# Z20K14xM register map
Vendor: Zhixin Semiconductor; Series: Z20K14xM; File version: 0.1.0
CPU: CM4 r0p1, little endian, no MPU, FPU, 4 interrupt priority bits
Registers are 32-bit, read-write, reset 0x0 unless marked. A register's access mark holds for its fields unless they carry their own. Offsets are from the block's base; [hi:lo] are bit positions.

## PMU
Base 0x4007D000
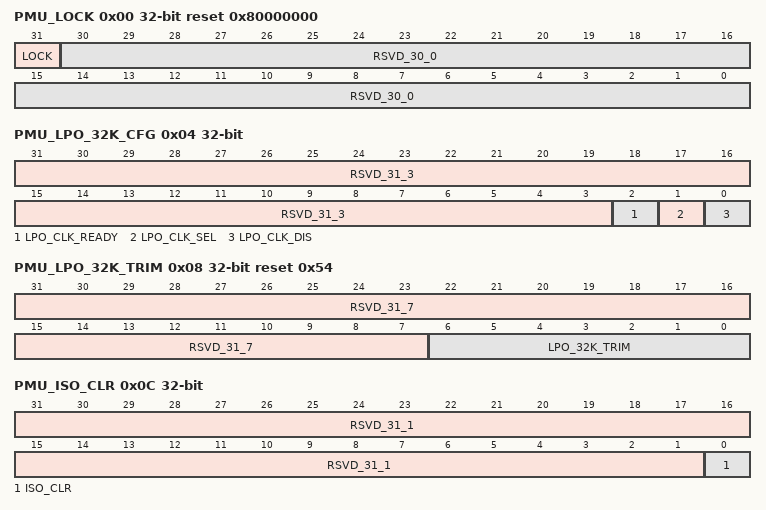
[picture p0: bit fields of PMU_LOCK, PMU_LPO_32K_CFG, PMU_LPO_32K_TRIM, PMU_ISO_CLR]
0x00 PMU_LOCK reset 0x80000000 — PMU lock protection register(PMU_LOCK_USER)
  [31] LOCK — PMU LOCK protection bit.
  [30:0] RSVD_30_0 — reserve
0x04 PMU_LPO_32K_CFG — PMU LPO32K control register(PMU_LPO32K_CFG)
  [31:3] RSVD_31_3 — reserve
  [2] LPO_CLK_READY — LPO raw clock ready flag.
  [1] LPO_CLK_SEL — LPO clock select bit.
  [0] LPO_CLK_DIS — LPO clock disable bit
0x08 PMU_LPO_32K_TRIM reset 0x54 — PMU LPO32K trim reigster(PMU_LPO32K_TRIM)
  [31:7] RSVD_31_7 — reserve
  [6:0] LPO_32K_TRIM
0x0C PMU_ISO_CLR — PMU isolation clear register(PMU_ISO_CLR)
  [31:1] RSVD_31_1 — reserve
  [0] ISO_CLR — isolation w1c clear bit.
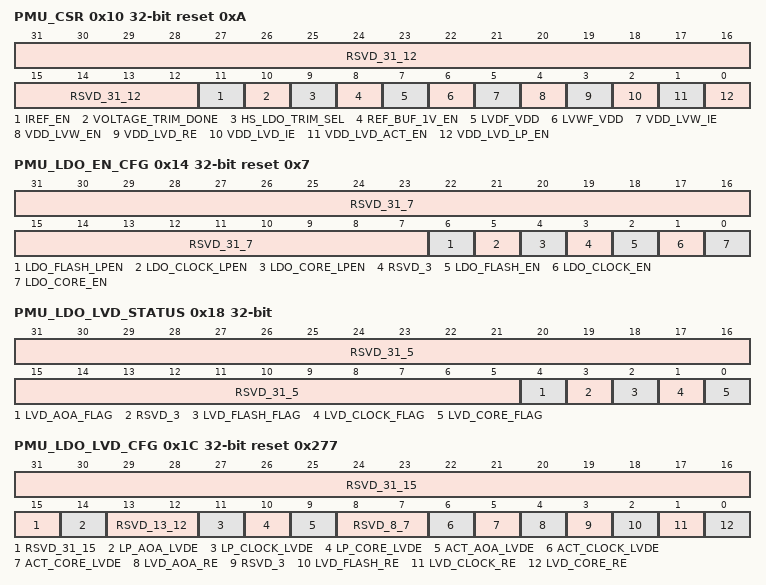
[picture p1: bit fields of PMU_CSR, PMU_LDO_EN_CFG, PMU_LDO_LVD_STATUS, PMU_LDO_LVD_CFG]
0x10 PMU_CSR reset 0xA — PMU control and status register(PMU_CSR)
  [31:12] RSVD_31_12 — reserve
  [11] IREF_EN — iref1uA enable bit
  [10] VOLTAGE_TRIM_DONE — voltage trim done flag
  [9] HS_LDO_TRIM_SEL — high speed trim select bit
  [8] REF_BUF_1V_EN — Reference 1V output enable with buf control
  [7] LVDF_VDD — VDD5v LVD flag
  [6] LVWF_VDD — VDD5v LVW detect flag
  [5] VDD_LVW_IE — VDD5v LVW interrupt enable
  [4] VDD_LVW_EN — VDD5v LVW detect control bit.
  [3] VDD_LVD_RE — VDD5v LVD reset enable control bit
  [2] VDD_LVD_IE — VDD5v LVD interrupt enable control
  [1] VDD_LVD_ACT_EN — VDD5v LVD detect control bit under active mode
  [0] VDD_LVD_LP_EN — VDD5v LVD detect control bit under low power mode
0x14 PMU_LDO_EN_CFG reset 0x7 — PMU LDO enable configure register(PMU_LDO_EN_CFG)
  [31:7] RSVD_31_7 — reserve
  [6] LDO_FLASH_LPEN — LDO-flash low drive strength mode enable under stop mode
  [5] LDO_CLOCK_LPEN — LDO-clock low drive strength mode enable under stop mode
  [4] LDO_CORE_LPEN — LDO-core low drive strength enable uner stop mode
  [3] RSVD_3 — reserve
  [2] LDO_FLASH_EN — LDO-flash regulator enable control
  [1] LDO_CLOCK_EN — LDO-clock regulator enable control
  [0] LDO_CORE_EN — LDO-core regulator enable control
0x18 PMU_LDO_LVD_STATUS — PMU LDO LVD status register(PMU_LDO_LVD_STATUS)
  [31:5] RSVD_31_5 — reserve
  [4] LVD_AOA_FLAG — always-on analog LDO LVD flag
  [3] RSVD_3 — reserve
  [2] LVD_FLASH_FLAG — LDO flash LVD flag
  [1] LVD_CLOCK_FLAG — LDO clock LVD flag
  [0] LVD_CORE_FLAG — LDO core LVD flag
0x1C PMU_LDO_LVD_CFG reset 0x277 — PMU LDO LVD configure register(PMU_LDO_LVD_CFG)
  [31:15] RSVD_31_15 — reserve
  [14] LP_AOA_LVDE — PMU always-on LDO-aoa LVD detect control under low power mode
  [13:12] RSVD_13_12 — reserve
  [11] LP_CLOCK_LVDE — PMU LDO-clock LVD detect control under low power mode
  [10] LP_CORE_LVDE — PMU LDO-core LVD detect control under low power mode
  [9] ACT_AOA_LVDE — PMU LDO-aoa LVD detect control under active mode
  [8:7] RSVD_8_7 — reserve
  [6] ACT_CLOCK_LVDE — PMU LDO-clock LVD detect control under active mode
  [5] ACT_CORE_LVDE — PMU LDO-core LVD detect control under active mode
  [4] LVD_AOA_RE — PMU LDO-aoa LVD reset enable control
  [3] RSVD_3 — reserve
  [2] LVD_FLASH_RE — PMU LDO-flash LVD reset enable control
  [1] LVD_CLOCK_RE — PMU LDO-clock LVD reset enable control
  [0] LVD_CORE_RE — PMU LDO-core LVD reset enable control
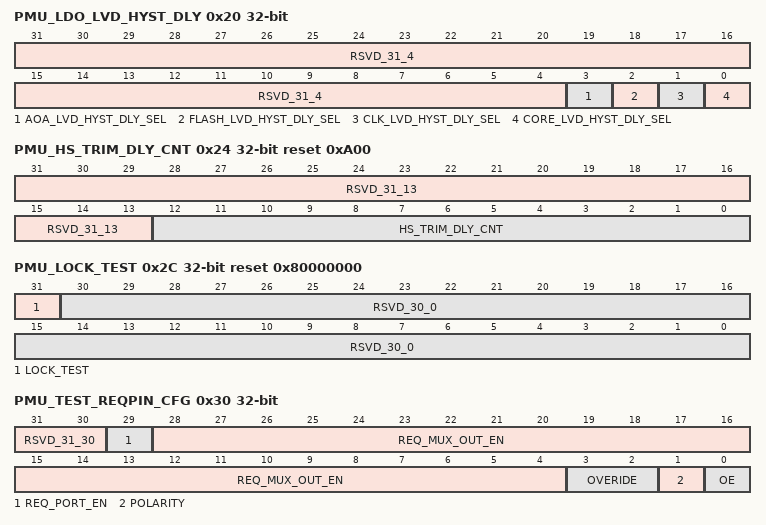
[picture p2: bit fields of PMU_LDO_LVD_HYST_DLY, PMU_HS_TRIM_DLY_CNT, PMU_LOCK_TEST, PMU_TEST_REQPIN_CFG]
0x20 PMU_LDO_LVD_HYST_DLY — PMU LDO LVD delay configure register(PMU_LVD_HYST_DLY)
  [31:4] RSVD_31_4 — reserve
  [3] AOA_LVD_HYST_DLY_SEL — aoa-lvd_hyst select
  [2] FLASH_LVD_HYST_DLY_SEL — flash-lvd_hyst select
  [1] CLK_LVD_HYST_DLY_SEL — clk-lvd_hyst select
  [0] CORE_LVD_HYST_DLY_SEL — core-lvd_hyst select
0x24 PMU_HS_TRIM_DLY_CNT reset 0xA00 — PMU reserve1 register (PMU_RESERVE1)
  [31:13] RSVD_31_13 — reserve
  [12:0] HS_TRIM_DLY_CNT — delay counter for switch between hsrun and run
0x28 PMU_RESERVE2 — PMU reserve2 register (PMU_RESERVE2)
  [31:0] RSVD_31_0 — reserve
0x2C PMU_LOCK_TEST reset 0x80000000 — reserve for user , doest not suggest user write this regsiter though no hardfault during write access. PMU lock protection for PMU test mode registers(PMU_LOCK_TEST)
  [31] LOCK_TEST — PMU LOCK test protection bit
  [30:0] RSVD_30_0 — reserve
0x30 PMU_TEST_REQPIN_CFG — PMU request pin observe register(PMU_TEST_REQPIN)
  [31:30] RSVD_31_30 — reserve
  [29] REQ_PORT_EN — Request pin port enable control
  [28:4] REQ_MUX_OUT_EN — Request pin mux output
  [3:2] OVERIDE — Request pin override enable
  [1] POLARITY — Request pin polarity control
  [0] OE — Request pin output enable
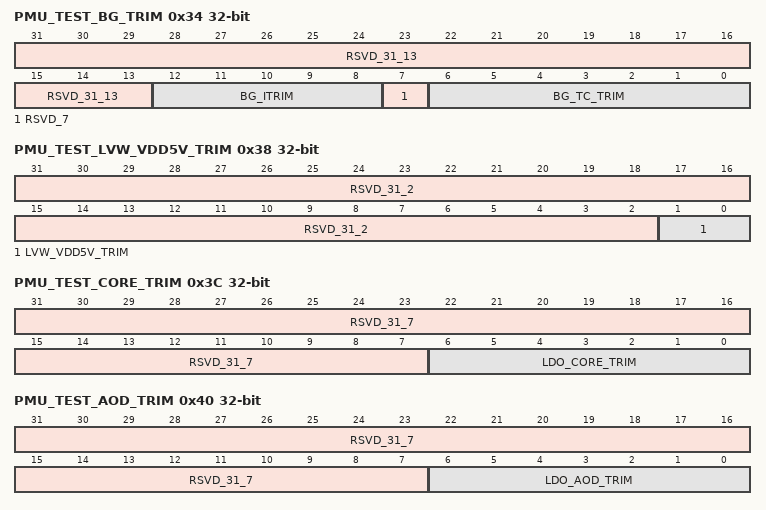
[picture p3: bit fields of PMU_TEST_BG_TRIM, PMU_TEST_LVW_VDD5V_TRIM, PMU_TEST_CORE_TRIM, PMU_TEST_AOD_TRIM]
0x34 PMU_TEST_BG_TRIM — PMU test bangap trim register(PMU_TEST_BG_TRIM)
  [31:13] RSVD_31_13 — reserve
  [12:8] BG_ITRIM — BandGap current reference trim
  [7] RSVD_7 — reserve
  [6:0] BG_TC_TRIM — Bandgap temperature trim
0x38 PMU_TEST_LVW_VDD5V_TRIM — PMU test LVW VDD5V trim register(PMU_TEST_LVW_VDD5V_TRIM)
  [31:2] RSVD_31_2 — reserve
  [1:0] LVW_VDD5V_TRIM — VDD5v LVW trim bits
0x3C PMU_TEST_CORE_TRIM — PMU test CORE trim register(PMU_TEST_CORE_TRIM)
  [31:7] RSVD_31_7 — reserve
  [6:0] LDO_CORE_TRIM — LDO CORE trim bits
0x40 PMU_TEST_AOD_TRIM — PMU test AOD trim register(PMU_TEST_AOD_TRIM)
  [31:7] RSVD_31_7 — reserve
  [6:0] LDO_AOD_TRIM — LDO-aod trim bits
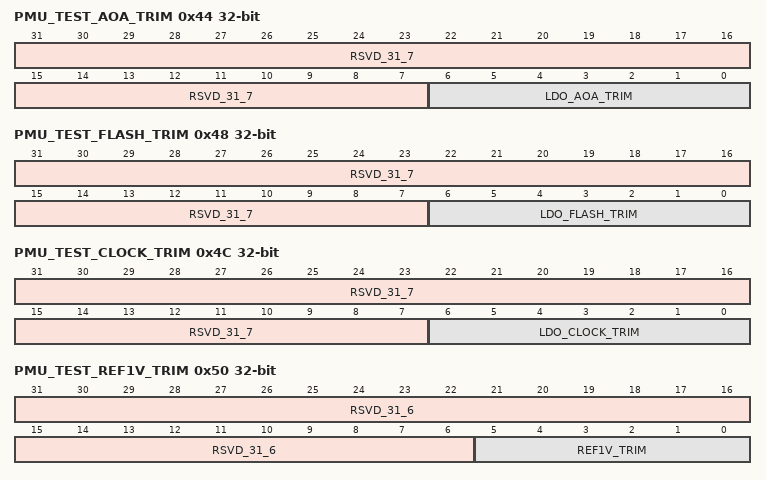
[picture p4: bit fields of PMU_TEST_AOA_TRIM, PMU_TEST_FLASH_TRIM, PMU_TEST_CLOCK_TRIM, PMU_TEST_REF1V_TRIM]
0x44 PMU_TEST_AOA_TRIM — PMU test AOA trim register(PMU_TEST_AOA_TRIM)
  [31:7] RSVD_31_7 — reserve
  [6:0] LDO_AOA_TRIM — LDO-aoa trim bits
0x48 PMU_TEST_FLASH_TRIM — PMU test FLASH trim register(PMU_TEST_FLASH_TRIM)
  [31:7] RSVD_31_7 — reserve
  [6:0] LDO_FLASH_TRIM — LDO-flash trim bits
0x4C PMU_TEST_CLOCK_TRIM — PMU test CLOCK trim register(PMU_TEST_CLOCK_TRIM)
  [31:7] RSVD_31_7 — reserve
  [6:0] LDO_CLOCK_TRIM — LDO-clock trim bits
0x50 PMU_TEST_REF1V_TRIM — PMU test REF1V trim regsiter(PMU_TEST_REF1V_TRIM)
  [31:6] RSVD_31_6 — reserve
  [5:0] REF1V_TRIM — Bandgap reference 1v trim bits
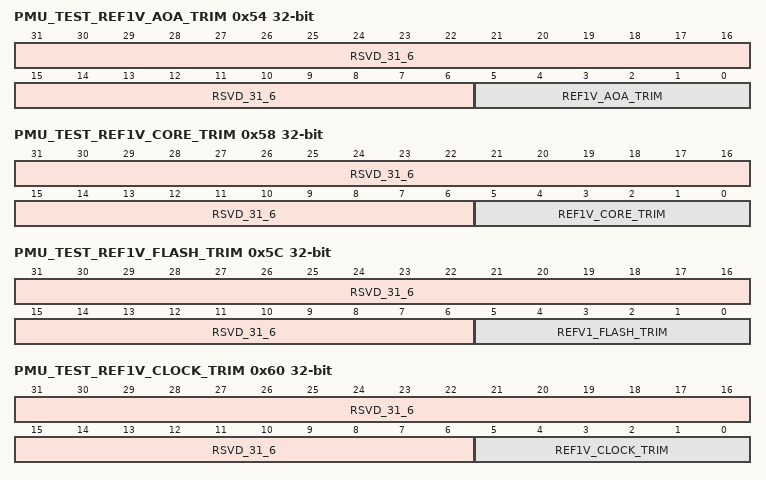
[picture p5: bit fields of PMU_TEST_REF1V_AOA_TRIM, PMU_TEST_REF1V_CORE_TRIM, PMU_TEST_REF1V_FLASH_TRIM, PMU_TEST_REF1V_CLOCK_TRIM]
0x54 PMU_TEST_REF1V_AOA_TRIM — PMU test AOA REF1V trim register(PMU_TEST_REF1V_AOA_TRIM)
  [31:6] RSVD_31_6 — reserve
  [5:0] REF1V_AOA_TRIM — LDO-aoa reference 1V trim
0x58 PMU_TEST_REF1V_CORE_TRIM — PMU test CORE REF1V trim register(PMU_TEST_REF1V_CORE_TRIM)
  [31:6] RSVD_31_6 — reserve
  [5:0] REF1V_CORE_TRIM — LDO-core reference 1V trim
0x5C PMU_TEST_REF1V_FLASH_TRIM — PMU test FLASH REF1V trim register(PMU_TEST_REF1V_FLASH_TRIM)
  [31:6] RSVD_31_6 — reserve
  [5:0] REFV1_FLASH_TRIM — LDO-flash reference 1V trim
0x60 PMU_TEST_REF1V_CLOCK_TRIM — PMU test CLOCK REF1V trim register(PMU_TEST_REF1V_CLOCK_TRIM)
  [31:6] RSVD_31_6 — reserve
  [5:0] REF1V_CLOCK_TRIM — LDO-clock reference 1V trim
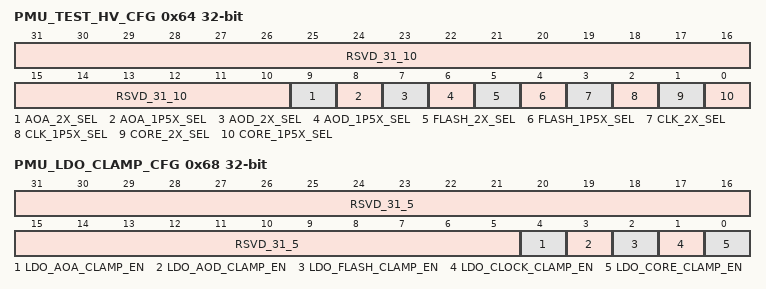
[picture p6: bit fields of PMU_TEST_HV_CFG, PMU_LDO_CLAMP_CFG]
0x64 PMU_TEST_HV_CFG — PMU test high voltage configure register(PMU_TEST_HV_CFG)
  [31:10] RSVD_31_10 — reserve
  [9] AOA_2X_SEL — ldo-aoa 2x select
  [8] AOA_1P5X_SEL — ldo-aoa 1p5x select
  [7] AOD_2X_SEL — ldo-aod 2x select
  [6] AOD_1P5X_SEL — ldo-aod 1p5x select
  [5] FLASH_2X_SEL — ldo-flash 2x select
  [4] FLASH_1P5X_SEL — ldo-flash 1p5x select
  [3] CLK_2X_SEL — ldo-clock 2x select
  [2] CLK_1P5X_SEL — ldo-clock 1p5x select
  [1] CORE_2X_SEL — ldo-core 2x select
  [0] CORE_1P5X_SEL — ldo-core 1p5x select
0x68 PMU_LDO_CLAMP_CFG — PMU LDO clamp configure register(PMU_LDO_CLAMP_CFG)
  [31:5] RSVD_31_5 — reserve
  [4] LDO_AOA_CLAMP_EN — ldo-aoa clamp enable
  [3] LDO_AOD_CLAMP_EN — ldo-aod clamp enable
  [2] LDO_FLASH_CLAMP_EN — ldo-flash clamp enable
  [1] LDO_CLOCK_CLAMP_EN — ldo-clock clamp enable
  [0] LDO_CORE_CLAMP_EN — ldo-core clamp enable
